AUTOSAR XML (schema 00048)
package /Eps_Repository/ActiveReturn/ActiveReturn
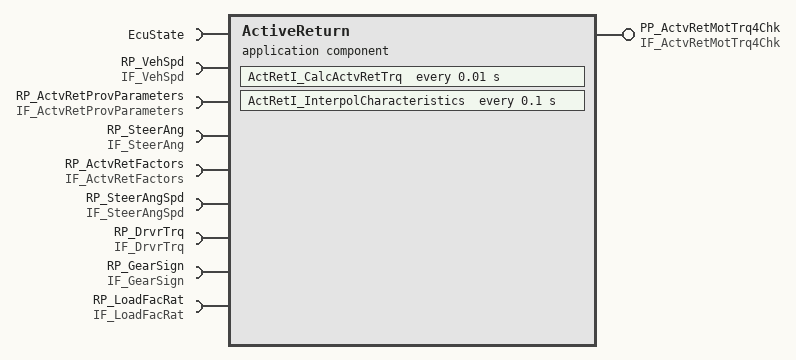
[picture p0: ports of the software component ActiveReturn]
  application sw component type ActiveReturn
    5 x require port:
      EcuState: required-interface=EcuState
      RP_VehSpd: required-com-specs=[{data-element=AbsAvgVehSpd, init-value=0}, {data-element=AbsMaxSafeVehSpd, init-value=0}], required-interface=IF_VehSpd
      RP_ActvRetProvParameters: required-interface=IF_ActvRetProvParameters
        required-com-specs:
          Get_ActvRetFilFac
          Get_ActvRetMaxMotTrq
          Get_ActvRetNomSteerSpd
          Get_ActvRetMotTrqGain
          Get_ActvRetRetTrqFactDepOnDrvr
          Get_ActvRetSteerSpdFactDepOnDrvr
          Get_ActvRetSteerSpdGradAftInvld
          Get_ActvRetSteerSpdAmp
          Get_ActvRetSteerSpdFact
      RP_SteerAng: required-com-specs=[{data-element=SteerAng, init-value=0}, {data-element=SteerAngSt, init-value=0}], required-interface=IF_SteerAng
      RP_ActvRetFactors: required-com-specs=[{data-element=ActvRetFuncFac, init-value=0}, {data-element=ActvRetSpdFac, init-value=0}], required-interface=IF_ActvRetFactors
    provide port PP_ActvRetMotTrq4Chk: nonqueued-sender-com-spec{data-element=ActvRetMotTrq4Chk, init-value=0}, provided-interface=IF_ActvRetMotTrq4Chk
    4 x require port:
      RP_SteerAngSpd: nonqueued-receiver-com-spec{data-element=SteerAngSpd, init-value=0}, required-interface=IF_SteerAngSpd
      RP_DrvrTrq: nonqueued-receiver-com-spec{data-element=DrvrTrq, init-value=0}, required-interface=IF_DrvrTrq
      RP_GearSign: nonqueued-receiver-com-spec{data-element=GearSign, init-value=0}, required-interface=IF_GearSign
      RP_LoadFacRat: nonqueued-receiver-com-spec{data-element=LoadFacRat, init-value=1}, required-interface=IF_LoadFacRat
    behavior IB_ActiveReturn: data-type-mapping=[DTMS_ActvRet, DTMS_ActvRet_L_Adpr, DTMS_ActvRetCdp], handle-termination-and-restart=NO-SUPPORT
      ar-typed-per-instance-memorys:
        data PIM_ActvRetSpdFacFilt: sw-calibration-access=READ-ONLY, type=ADT_ActvRetSpdFacFilt, init-value=1
        data PIM_ActvRetRetSpdDiff: sw-calibration-access=READ-ONLY, type=ADT_ActvRetRetSpdDiff, init-value=0
        data PIM_ActvRetTrqFacFilt: sw-calibration-access=READ-ONLY, type=ADT_ActvRetTrqFacFilt, init-value=1
      timing event TE_ActiveReturn_CalcActvRetTrq: start-on-event=ActRetI_CalcActvRetTrq, period=0.01
        disabled-mode:
          EcuState.ApplicationModes.EcuInit
          EcuState.ApplicationModes.ApplicationInit
          EcuState.ApplicationModes.PostRun
          EcuState.ApplicationModes.Error
          EcuState.ApplicationModes.ApplicationOff
      timing event TE_ActiveReturn_InterpolCharacteristics: start-on-event=ActRetI_InterpolCharacteristics, period=0.1
        disabled-mode:
          EcuState.ApplicationModes.EcuInit
          EcuState.ApplicationModes.ApplicationInit
          EcuState.ApplicationModes.PostRun
          EcuState.ApplicationModes.Error
          EcuState.ApplicationModes.ApplicationOff
      explicit-inter-runnable-variables:
        4 x data, all with sw-calibration-access=READ-ONLY:
          IRV_MotTrqGain: type=ADT_MotTrqGain, init-value=0
          IRV_ActvRetSpdFacFilt: type=ADT_ActvRetSpdFacFilt, init-value=1
          IRV_ActvRetRetSpdDiff: type=ADT_ActvRetRetSpdDiff, init-value=0
          IRV_ActvRetTrqFacFilt: type=ADT_ActvRetTrqFacFilt, init-value=1
      runnable ActRetI_InterpolCharacteristics
        data-receive-point-by-arguments:
          access DRP_RP_VehSpd_AbsAvgVehSpd: accessed-variable=RP_VehSpd.AbsAvgVehSpd
        sync call SSCP_RP_ActvRetProvParameters_Get_ActvRetMotTrqGain: operation=RP_ActvRetProvParameters.Get_ActvRetMotTrqGain, timeout=0
        written-local-variables:
          access IRVWA_IRV_MotTrqGain: accessed-variable=IRV_MotTrqGain
      runnable ActRetI_CalcActvRetTrq: symbol=ActRetI_CalcActiveReturnTorque
        data-receive-point-by-arguments:
          9 x access:
            DRP_RP_SteerAngSpd_SteerAngSpd: accessed-variable=RP_SteerAngSpd.SteerAngSpd
            DRP_RP_DrvrTrq_DrvrTrq: accessed-variable=RP_DrvrTrq.DrvrTrq
            DRP_RP_GearSign_GearSign: accessed-variable=RP_GearSign.GearSign
            DRP_RP_LoadFacRat_LoadFacRat: accessed-variable=RP_LoadFacRat.LoadFacRat
            DRP_RP_SteerAng_SteerAng: accessed-variable=RP_SteerAng.SteerAng
            DRP_RP_SteerAng_SteerAngSt: accessed-variable=RP_SteerAng.SteerAngSt
            DRP_RP_VehSpd_AbsAvgVehSpd: accessed-variable=RP_VehSpd.AbsAvgVehSpd
            DRP_RP_ActvRetFactors_ActvRetFuncFac: accessed-variable=RP_ActvRetFactors.ActvRetFuncFac
            DRP_RP_ActvRetFactors_ActvRetSpdFac: accessed-variable=RP_ActvRetFactors.ActvRetSpdFac
        data-send-points:
          access DSP_PP_ActvRetMotTrq4Chk_ActvRetMotTrq4Chk: accessed-variable=PP_ActvRetMotTrq4Chk.ActvRetMotTrq4Chk
        read-local-variables:
          access IRVRA_IRV_MotTrqGain: accessed-variable=IRV_MotTrqGain
        9 x sync call, all with timeout=0:
          SSCP_RP_ActvRetProvParameters_Get_ActvRetFilFac: operation=RP_ActvRetProvParameters.Get_ActvRetFilFac
          SSCP_RP_ActvRetProvParameters_Get_ActvRetSteerSpdFactDepOnDrvr: operation=RP_ActvRetProvParameters.Get_ActvRetSteerSpdFactDepOnDrvr
          SSCP_RP_ActvRetProvParameters_Get_ActvRetRetTrqFactDepOnDrvr: operation=RP_ActvRetProvParameters.Get_ActvRetRetTrqFactDepOnDrvr
          SSCP_RP_ActvRetProvParameters_Get_ActvRetSteerSpdFact: operation=RP_ActvRetProvParameters.Get_ActvRetSteerSpdFact
          SSCP_RP_ActvRetProvParameters_Get_ActvRetSteerSpdGradAftInvld: operation=RP_ActvRetProvParameters.Get_ActvRetSteerSpdGradAftInvld
          SSCP_RP_ActvRetProvParameters_Get_ActvRetSteerSpdAmp: operation=RP_ActvRetProvParameters.Get_ActvRetSteerSpdAmp
          SSCP_RP_ActvRetProvParameters_Get_ActvRetMaxMotTrq: operation=RP_ActvRetProvParameters.Get_ActvRetMaxMotTrq
          SSCP_RP_ActvRetProvParameters_Get_ActvRetNomSteerSpd: operation=RP_ActvRetProvParameters.Get_ActvRetNomSteerSpd
          SSCP_RP_ActvRetProvParameters_Get_ActvRetMaxMotTrqAftLoadFac: operation=RP_ActvRetProvParameters.Get_ActvRetMaxMotTrqAftLoadFac
        written-local-variables:
          access IRVWA_IRV_ActvRetSpdFacFilt: accessed-variable=IRV_ActvRetSpdFacFilt
          access IRVWA_IRV_ActvRetTrqFacFilt: accessed-variable=IRV_ActvRetTrqFacFilt
          access IRVWA_IRV_ActvRetRetSpdDiff: accessed-variable=IRV_ActvRetRetSpdDiff
package /Eps_Repository/ActiveReturn/ActiveReturn/DataTypeMappingSets
  data type mapping set DTMS_ActvRet: mode-request-type-map{implementation-data-type=uint8, mode-group=ApplicationModes}
    data-type-maps:
      application-data-type=ADT_ActvRetMotTrq4Chk, implementation-data-type=IDT_ActvRetMotTrq4Chk
      application-data-type=ADT_ActvRetRetSpdDiff, implementation-data-type=IDT_ActvRetRetSpdDiff
      application-data-type=ADT_MotTrqGain, implementation-data-type=IDT_MotTrqGain
      application-data-type=ADT_ActvRetNomSteerSpdFrac, implementation-data-type=IDT_ActvRetNomSteerSpdFrac
      application-data-type=ADT_ActvRetSpdFacFilt, implementation-data-type=IDT_ActvRetSpdFacFilt
      application-data-type=ADT_ActvRetTrqFacFilt, implementation-data-type=IDT_ActvRetTrqFacFilt
      application-data-type=ADT_ActvRetNomSteerSpdIdx, implementation-data-type=IDT_ActvRetNomSteerSpdIdx
package /Eps_Repository/ActiveReturn/ActiveReturn/Interfaces
  mode declaration group ApplicationModes: category=ALPHABETIC_ORDER, initial-mode=EcuInit
    8 x mode:
      ApplicationInit
      ApplicationOff
      EcuInit
      Error
      FailOp
      Normal
      PostRun
      Production
  mode switch interface EcuState
    mode group ApplicationModes: type=ApplicationModes
  sender receiver interface IF_ActvRetMotTrq4Chk: invalidation-policy{data-element=ActvRetMotTrq4Chk, handle-invalid=KEEP}
    data ActvRetMotTrq4Chk: sw-addr-method=DAMOS_RAM_DTA, sw-calibration-access=READ-ONLY, type=ADT_ActvRetMotTrq4Chk
package /Eps_Repository/ActiveReturn/ActiveReturn/ApplicationDataTypes
  7 x app type, all with category=VALUE:
    ADT_ActvRetMotTrq4Chk: compu-method=CM_MMOT, range phys -3..3, raw -3072..3072
    ADT_ActvRetRetSpdDiff: compu-method=CM_SAS_8, range phys -1500..1500, raw -12000..12000
    ADT_MotTrqGain: compu-method=CM_RIGHTSH10NP, range phys 0..3, raw 0..3072
    ADT_ActvRetNomSteerSpdFrac: compu-method=CM_RIGHTSH16NP, range phys 0..1, raw 0..65535
    ADT_ActvRetSpdFacFilt: compu-method=CM_RIGHTSH20NP, range phys 0..1, raw 0..1048576
    ADT_ActvRetTrqFacFilt: compu-method=CM_RIGHTSH20NP, range phys 0..1, raw 0..1048576
    ADT_ActvRetNomSteerSpdIdx: compu-method=CM_ZU0, range phys 0..254, raw 0..254
package /Eps_Repository/ActiveReturn/ActiveReturn/ImplementationDataTypes
  7 x impl type, all with category=TYPE_REFERENCE:
    IDT_ActvRetMotTrq4Chk: range phys -3..3, raw -3072..3072, implementation-data-type=sint16, invalid-value=Value:32767
    IDT_ActvRetRetSpdDiff: range phys -1500..1500, raw -12000..12000, implementation-data-type=sint16, invalid-value=Value:32767
    IDT_MotTrqGain: range phys 0..3, raw 0..3072, implementation-data-type=uint16, invalid-value=Value:65535
    IDT_ActvRetNomSteerSpdFrac: range phys 0..1, raw 0..65535, implementation-data-type=uint16, invalid-value=Value:65535
    IDT_ActvRetSpdFacFilt: range phys 0..1, raw 0..1048576, implementation-data-type=sint32, invalid-value=Value:2147483647
    IDT_ActvRetTrqFacFilt: range phys 0..1, raw 0..1048576, implementation-data-type=sint32, invalid-value=Value:2147483647
    IDT_ActvRetNomSteerSpdIdx: range phys 0..254, raw 0..254, implementation-data-type=uint8, invalid-value=Value:255
package /Eps_Repository/ActiveReturn/ActiveReturn/SWAddrMethod
  sw addr method DAMOS_RAM_DTA: memory-allocation-keyword-policy=ADDR-METHOD-SHORT-NAME, section-initialization-policy=INIT, section-type=VAR
